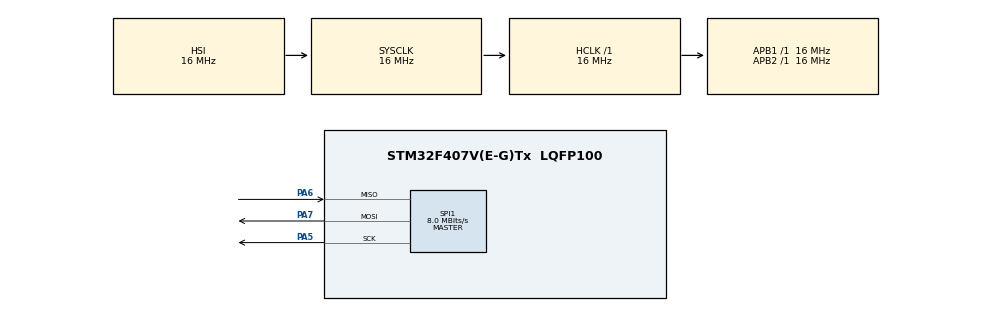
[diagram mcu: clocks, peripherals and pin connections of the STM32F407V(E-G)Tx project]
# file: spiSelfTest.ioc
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Mcu.Family=STM32F4
PA6.Mode=Full_Duplex_Master
PH0-OSC_IN.Signal=RCC_OSC_IN
RCC.CortexFreq_Value=16000000
PA7.Mode=Full_Duplex_Master
SPI1.VirtualType=VM_MASTER
ProjectManager.StackSize=0x400
PA13.Signal=SYS_JTMS-SWDIO
ProjectManager.TargetToolchain=STM32CubeIDE
SPI1.Direction=SPI_DIRECTION_2LINES
SPI1.CalculateBaudRate=8.0 MBits/s
RCC.LSE_VALUE=32768
RCC.AHBFreq_Value=16000000
PH0-OSC_IN.Mode=HSE-External-Oscillator
PA5.Signal=SPI1_SCK
RCC.HSE_VALUE=25000000
board=custom
RCC.VCOOutputFreq_Value=192000000
RCC.APB2Freq_Value=16000000
SPI1.Mode=SPI_MODE_MASTER
PA14.Mode=Serial_Wire
PH1-OSC_OUT.Signal=RCC_OSC_OUT
PA13.Mode=Serial_Wire
Mcu.Name=STM32F407V(E-G)Tx
PH1-OSC_OUT.Mode=HSE-External-Oscillator
RCC.SYSCLKFreq_VALUE=16000000
Mcu.Package=LQFP100
PA6.Signal=SPI1_MISO
PA14.Signal=SYS_JTCK-SWCLK
ProjectManager.HeapSize=0x200
RCC.HSI_VALUE=16000000
NVIC.PriorityGroup=NVIC_PRIORITYGROUP_4
RCC.APB1Freq_Value=16000000
PA5.Mode=Full_Duplex_Master
PA7.Signal=SPI1_MOSI

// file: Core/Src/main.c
/* USER CODE BEGIN Header */
/**
  ******************************************************************************
  * @file           : main.c
  * @brief          : Main program body
  ******************************************************************************
  * @attention
  *
  * <h2><center>&copy; Copyright (c) 2020 STMicroelectronics.
  * All rights reserved.</center></h2>
  *
  * This software component is licensed by ST under BSD 3-Clause license,
  * the "License"; You may not use this file except in compliance with the
  * License. You may obtain a copy of the License at:
  *                        opensource.org/licenses/BSD-3-Clause
  *
  ******************************************************************************
  */
/* USER CODE END Header */
#include "main.h"

SPI_HandleTypeDef hspi1;

/* USER CODE BEGIN PV */
uint8_t al[3],gonder[3]={'A','L','O'};

uint8_t veri[7][11]={{"ATAV\r"},{"BiLaL\r"},
		{"Levo\r"},{"Omer\r"},{"EDSon\r"},{"Yilmaz\r"},{"##########\r"}};
/* USER CODE END PV */

void SystemClock_Config(void);
static void MX_GPIO_Init(void);
static void MX_SPI1_Init(void);

int main(void)
{

  /* MCU Configuration--------------------------------------------------------*/

  /* Reset of all peripherals, Initializes the Flash interface and the Systick. */
  HAL_Init();

  /* Configure the system clock */
  SystemClock_Config();

  /* Initialize all configured peripherals */
  MX_GPIO_Init();
  MX_SPI1_Init();

  /* Infinite loop */
  /* USER CODE BEGIN WHILE */
  while (1)
  {
	  HAL_SPI_TransmitReceive(&hspi1, gonder, al, 3, 1000);
	  HAL_Delay(1000);

	  for (int i=0;i<7;i++)
	  {
		  HAL_SPI_Transmit(&hspi1, veri[i], sizeof(veri[i]), 1000);
		  HAL_Delay(250);
	  }
    /* USER CODE END WHILE */

  }
}

void SystemClock_Config(void)
{
  RCC_OscInitTypeDef RCC_OscInitStruct = {0};
  RCC_ClkInitTypeDef RCC_ClkInitStruct = {0};

  /** Configure the main internal regulator output voltage
  */
  __HAL_RCC_PWR_CLK_ENABLE();
  __HAL_PWR_VOLTAGESCALING_CONFIG(PWR_REGULATOR_VOLTAGE_SCALE1);
  /** Initializes the RCC Oscillators according to the specified parameters
  * in the RCC_OscInitTypeDef structure.
  */
  RCC_OscInitStruct.OscillatorType = RCC_OSCILLATORTYPE_HSI;
  RCC_OscInitStruct.HSIState = RCC_HSI_ON;
  RCC_OscInitStruct.HSICalibrationValue = RCC_HSICALIBRATION_DEFAULT;
  RCC_OscInitStruct.PLL.PLLState = RCC_PLL_NONE;
  if (HAL_RCC_OscConfig(&RCC_OscInitStruct) != HAL_OK)
  {
    Error_Handler();
  }
  /** Initializes the CPU, AHB and APB buses clocks
  */
  RCC_ClkInitStruct.ClockType = RCC_CLOCKTYPE_HCLK|RCC_CLOCKTYPE_SYSCLK
                              |RCC_CLOCKTYPE_PCLK1|RCC_CLOCKTYPE_PCLK2;
  RCC_ClkInitStruct.SYSCLKSource = RCC_SYSCLKSOURCE_HSI;
  RCC_ClkInitStruct.AHBCLKDivider = RCC_SYSCLK_DIV1;
  RCC_ClkInitStruct.APB1CLKDivider = RCC_HCLK_DIV1;
  RCC_ClkInitStruct.APB2CLKDivider = RCC_HCLK_DIV1;

  if (HAL_RCC_ClockConfig(&RCC_ClkInitStruct, FLASH_LATENCY_0) != HAL_OK)
  {
    Error_Handler();
  }
}

static void MX_SPI1_Init(void)
{

  /* SPI1 parameter configuration*/
  hspi1.Instance = SPI1;
  hspi1.Init.Mode = SPI_MODE_MASTER;
  hspi1.Init.Direction = SPI_DIRECTION_2LINES;
  hspi1.Init.DataSize = SPI_DATASIZE_8BIT;
  hspi1.Init.CLKPolarity = SPI_POLARITY_LOW;
  hspi1.Init.CLKPhase = SPI_PHASE_1EDGE;
  hspi1.Init.NSS = SPI_NSS_SOFT;
  hspi1.Init.BaudRatePrescaler = SPI_BAUDRATEPRESCALER_2;
  hspi1.Init.FirstBit = SPI_FIRSTBIT_MSB;
  hspi1.Init.TIMode = SPI_TIMODE_DISABLE;
  hspi1.Init.CRCCalculation = SPI_CRCCALCULATION_DISABLE;
  hspi1.Init.CRCPolynomial = 10;
  if (HAL_SPI_Init(&hspi1) != HAL_OK)
  {
    Error_Handler();
  }

}

static void MX_GPIO_Init(void)
{

  /* GPIO Ports Clock Enable */
  __HAL_RCC_GPIOH_CLK_ENABLE();
  __HAL_RCC_GPIOA_CLK_ENABLE();

}

void Error_Handler(void)
{
  __disable_irq();
  while (1)
  {
  }
}

/************************ (C) COPYRIGHT STMicroelectronics *****END OF FILE****/
